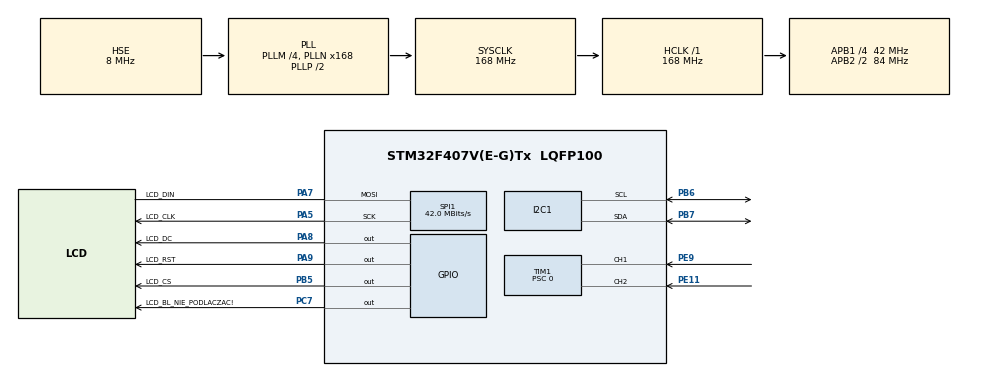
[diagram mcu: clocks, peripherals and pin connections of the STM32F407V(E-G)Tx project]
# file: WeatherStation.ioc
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Mcu.Family=STM32F4
Mcu.Name=STM32F407V(E-G)Tx
Mcu.Package=LQFP100
NVIC.PriorityGroup=NVIC_PRIORITYGROUP_4
NVIC.TIM4_IRQn=true\:0\:0\:false\:false\:true\:true
PA5.GPIO_Label=LCD_CLK
PA5.Mode=Simplex_Bidirectional_Master
PA5.Signal=SPI1_SCK
PA7.GPIO_Label=LCD_DIN
PA7.Mode=Simplex_Bidirectional_Master
PA7.Signal=SPI1_MOSI
PA8.GPIO_Label=LCD_DC
PA8.Signal=GPIO_Output
PA9.GPIO_Label=LCD_RST
PA9.Signal=GPIO_Output
PB5.GPIO_Label=LCD_CS
PB5.Signal=GPIO_Output
PB6.Mode=I2C
PB6.Signal=I2C1_SCL
PB7.Mode=I2C
PB7.Signal=I2C1_SDA
PC7.GPIO_Label=LCD_BL_NIE_PODLACZAC\!
PC7.Signal=GPIO_Output
PE11.Signal=S_TIM1_CH2
PE9.Signal=S_TIM1_CH1
PH0-OSC_IN.Mode=HSE-External-Oscillator
PH0-OSC_IN.Signal=RCC_OSC_IN
PH1-OSC_OUT.Mode=HSE-External-Oscillator
PH1-OSC_OUT.Signal=RCC_OSC_OUT
ProjectManager.HeapSize=0x200
ProjectManager.StackSize=0x400
ProjectManager.TargetToolchain=SW4STM32
RCC.48MHZClocksFreq_Value=84000000
RCC.AHBFreq_Value=168000000
RCC.APB1CLKDivider=RCC_HCLK_DIV4
RCC.APB1Freq_Value=42000000
RCC.APB1TimFreq_Value=84000000
RCC.APB2CLKDivider=RCC_HCLK_DIV2
RCC.APB2Freq_Value=84000000
RCC.APB2TimFreq_Value=168000000
RCC.CortexFreq_Value=168000000
RCC.HCLKFreq_Value=168000000
RCC.HSE_VALUE=8000000
RCC.HSI_VALUE=16000000
RCC.LSE_VALUE=32768
RCC.PLLM=4
RCC.PLLN=168
RCC.PLLSourceVirtual=RCC_PLLSOURCE_HSE
RCC.SYSCLKFreq_VALUE=168000000
RCC.SYSCLKSource=RCC_SYSCLKSOURCE_PLLCLK
RCC.VCOOutputFreq_Value=336000000
SH.S_TIM1_CH1.0=TIM1_CH1,Encoder_Interface
SH.S_TIM1_CH2.0=TIM1_CH2,Encoder_Interface
SPI1.CalculateBaudRate=42.0 MBits/s
SPI1.Direction=SPI_DIRECTION_1LINE
SPI1.Mode=SPI_MODE_MASTER
SPI1.VirtualType=VM_MASTER
TIM1.EncoderMode=TIM_ENCODERMODE_TI12
TIM1.IC1Filter=15
TIM1.IC2Filter=15
TIM1.Period=403
TIM1.Prescaler=0
TIM4.Period=8399
TIM4.Prescaler=9999
VP_TIM4_VS_ClockSourceINT.Mode=Internal
board=custom

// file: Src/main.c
/**
  ******************************************************************************
  * @file           : main.c
  * @brief          : Main program body
  ******************************************************************************
  ** This notice applies to any and all portions of this file
  * that are not between comment pairs USER CODE BEGIN and
  * USER CODE END. Other portions of this file, whether
  * inserted by the user or by software development tools
  * are owned by their respective copyright owners.
  *
  * COPYRIGHT(c) 2019 STMicroelectronics
  *
  * Redistribution and use in source and binary forms, with or without modification,
  * are permitted provided that the following conditions are met:
  *   1. Redistributions of source code must retain the above copyright notice,
  *      this list of conditions and the following disclaimer.
  *   2. Redistributions in binary form must reproduce the above copyright notice,
  *      this list of conditions and the following disclaimer in the documentation
  *      and/or other materials provided with the distribution.
  *   3. Neither the name of STMicroelectronics nor the names of its contributors
  *      may be used to endorse or promote products derived from this software
  *      without specific prior written permission.
  *
  * THIS SOFTWARE IS PROVIDED BY THE COPYRIGHT HOLDERS AND CONTRIBUTORS "AS IS"
  * AND ANY EXPRESS OR IMPLIED WARRANTIES, INCLUDING, BUT NOT LIMITED TO, THE
  * IMPLIED WARRANTIES OF MERCHANTABILITY AND FITNESS FOR A PARTICULAR PURPOSE ARE
  * DISCLAIMED. IN NO EVENT SHALL THE COPYRIGHT HOLDER OR CONTRIBUTORS BE LIABLE
  * FOR ANY DIRECT, INDIRECT, INCIDENTAL, SPECIAL, EXEMPLARY, OR CONSEQUENTIAL
  * DAMAGES (INCLUDING, BUT NOT LIMITED TO, PROCUREMENT OF SUBSTITUTE GOODS OR
  * SERVICES; LOSS OF USE, DATA, OR PROFITS; OR BUSINESS INTERRUPTION) HOWEVER
  * CAUSED AND ON ANY THEORY OF LIABILITY, WHETHER IN CONTRACT, STRICT LIABILITY,
  * OR TORT (INCLUDING NEGLIGENCE OR OTHERWISE) ARISING IN ANY WAY OUT OF THE USE
  * OF THIS SOFTWARE, EVEN IF ADVISED OF THE POSSIBILITY OF SUCH DAMAGE.
  *
  ******************************************************************************
  */
#include "main.h"
#include "stm32f4xx_hal.h"

/* USER CODE BEGIN Includes */
#include <string.h>
#include <stdlib.h>
#include <math.h>
#include "bmp280.h"
#include "st7735.h"
#include "fonts.h"
#include "images/widgets.h"

#define RADIUS 0.04
#define KM_H 3.6
#define T_TIM 0.5
#define ANGLE 15
/* USER CODE END Includes */

I2C_HandleTypeDef hi2c1;

SPI_HandleTypeDef hspi1;

TIM_HandleTypeDef htim1;
TIM_HandleTypeDef htim4;

/* USER CODE BEGIN PV */
/* Private variables ---------------------------------------------------------*/
BMP280_HandleTypedef bmp280;

float pressure, temperature, humidity;
float pressure_hPa;

volatile uint16_t pulse_count;
volatile uint16_t position1 = 0;
volatile uint16_t position2 = 0;
volatile uint16_t angle_remainder;
volatile float angular_velocity;
volatile float velocity;
/* USER CODE END PV */

void SystemClock_Config(void);
static void MX_GPIO_Init(void);
static void MX_I2C1_Init(void);
static void MX_TIM1_Init(void);
static void MX_SPI1_Init(void);
static void MX_TIM4_Init(void);

/* USER CODE BEGIN PFP */
/* Private function prototypes -----------------------------------------------*/
void HAL_TIM_PeriodElapsedCallback(TIM_HandleTypeDef *htim) {
    if (htim->Instance == TIM4) {
        pulse_count = TIM1->CNT;
        position2 = position1;
        position1 = pulse_count / 2;
        angle_remainder = abs(position2 - position1);
        if (angle_remainder > 300)
            angle_remainder = 400 - angle_remainder;
        angular_velocity = (angle_remainder * ANGLE / T_TIM) * M_PI / 180;
        velocity = angular_velocity * RADIUS * KM_H;
    }

}
/* USER CODE END PFP */

/* USER CODE BEGIN 0 */

/**
 * Initialize BME280 temperature, pressure and humidity sensor
 */
void sensor_init() {
	bmp280_init_default_params(&bmp280.params);
	bmp280.addr = BMP280_I2C_ADDRESS_1;
	bmp280.i2c = &hi2c1;
	bmp280_init(&bmp280, &bmp280.params);
}

/**
 * Initialize ST7735S LCD display
 */
void LCD_init() {
    ST7735_Init();
    ST7735_DrawImage(0, 0, 160, 128, (uint16_t *) widget);
    HAL_Delay(3000);

    ST7735_FillScreen(ST7735_BGCOLOR);
    ST7735_DrawImage(10, 7, 24, 24, (uint16_t *) termometer);
    ST7735_DrawImage(10, 37, 24, 24, (uint16_t *) barometer);
    ST7735_DrawImage(10, 67, 24, 24, (uint16_t *) humidity_img);
    ST7735_DrawImage(10, 97, 24, 24, (uint16_t *) wind);

    ST7735_DrawCircle(104, 15, 3, 0, 2, ST7735_BLACK);
    ST7735_WriteString(111, 11, "C", Font_11x18, ST7735_BLACK, ST7735_BGCOLOR);
    ST7735_WriteString(120, 41, "hPa", Font_11x18, ST7735_BLACK, ST7735_BGCOLOR);
    ST7735_WriteString(100, 71, "%", Font_11x18, ST7735_BLACK, ST7735_BGCOLOR);
    ST7735_WriteString(100, 101, "km/h", Font_11x18, ST7735_BLACK, ST7735_BGCOLOR);
}

void LCD_loop() {
    ST7735_WriteNumber(40, 11, temperature, Font_11x18, ST7735_BLACK, ST7735_BGCOLOR);
    ST7735_WriteNumber(40, 41, pressure_hPa, Font_11x18, ST7735_BLACK, ST7735_BGCOLOR);
    ST7735_WriteNumber(40, 71, humidity, Font_11x18, ST7735_BLACK, ST7735_BGCOLOR);
    if (velocity < 10) {
        ST7735_FillRectangle(84, 101, 11, 18, ST7735_BGCOLOR);
        ST7735_WriteNumber(40, 101, velocity, Font_11x18, ST7735_BLACK, ST7735_BGCOLOR);
    } else {
        ST7735_WriteNumber(40, 101, velocity, Font_11x18, ST7735_BLACK, ST7735_BGCOLOR);
    }
    HAL_Delay(500);
}

/* USER CODE END 0 */

int main(void)
{

  /* MCU Configuration----------------------------------------------------------*/

  /* Reset of all peripherals, Initializes the Flash interface and the Systick. */
  HAL_Init();

  /* Configure the system clock */
  SystemClock_Config();

  /* Initialize all configured peripherals */
  MX_GPIO_Init();
  MX_I2C1_Init();
  MX_TIM1_Init();
  MX_SPI1_Init();
  MX_TIM4_Init();
  /* USER CODE BEGIN 2 */
  	sensor_init();
    HAL_TIM_Encoder_Start(&htim1, TIM_CHANNEL_ALL);
    LCD_init();

    HAL_TIM_Base_Start_IT(&htim4);
  /* USER CODE END 2 */

  /* Infinite loop */
    while (1)
    {

  /* USER CODE BEGIN 3 */
        HAL_Delay(100);
        bmp280_read_float(&bmp280, &temperature, &pressure, &humidity);
        pressure_hPa = pressure / 100;

        LCD_loop();
    }
  /* USER CODE END 3 */

}

void SystemClock_Config(void)
{

  RCC_OscInitTypeDef RCC_OscInitStruct;
  RCC_ClkInitTypeDef RCC_ClkInitStruct;

    /**Configure the main internal regulator output voltage
    */
  __HAL_RCC_PWR_CLK_ENABLE();

  __HAL_PWR_VOLTAGESCALING_CONFIG(PWR_REGULATOR_VOLTAGE_SCALE1);

    /**Initializes the CPU, AHB and APB busses clocks
    */
  RCC_OscInitStruct.OscillatorType = RCC_OSCILLATORTYPE_HSE;
  RCC_OscInitStruct.HSEState = RCC_HSE_ON;
  RCC_OscInitStruct.PLL.PLLState = RCC_PLL_ON;
  RCC_OscInitStruct.PLL.PLLSource = RCC_PLLSOURCE_HSE;
  RCC_OscInitStruct.PLL.PLLM = 4;
  RCC_OscInitStruct.PLL.PLLN = 168;
  RCC_OscInitStruct.PLL.PLLP = RCC_PLLP_DIV2;
  RCC_OscInitStruct.PLL.PLLQ = 4;
  if (HAL_RCC_OscConfig(&RCC_OscInitStruct) != HAL_OK)
  {
    _Error_Handler(__FILE__, __LINE__);
  }

    /**Initializes the CPU, AHB and APB busses clocks
    */
  RCC_ClkInitStruct.ClockType = RCC_CLOCKTYPE_HCLK|RCC_CLOCKTYPE_SYSCLK
                              |RCC_CLOCKTYPE_PCLK1|RCC_CLOCKTYPE_PCLK2;
  RCC_ClkInitStruct.SYSCLKSource = RCC_SYSCLKSOURCE_PLLCLK;
  RCC_ClkInitStruct.AHBCLKDivider = RCC_SYSCLK_DIV1;
  RCC_ClkInitStruct.APB1CLKDivider = RCC_HCLK_DIV4;
  RCC_ClkInitStruct.APB2CLKDivider = RCC_HCLK_DIV2;

  if (HAL_RCC_ClockConfig(&RCC_ClkInitStruct, FLASH_LATENCY_5) != HAL_OK)
  {
    _Error_Handler(__FILE__, __LINE__);
  }

    /**Configure the Systick interrupt time
    */
  HAL_SYSTICK_Config(HAL_RCC_GetHCLKFreq()/1000);

    /**Configure the Systick
    */
  HAL_SYSTICK_CLKSourceConfig(SYSTICK_CLKSOURCE_HCLK);

  /* SysTick_IRQn interrupt configuration */
  HAL_NVIC_SetPriority(SysTick_IRQn, 0, 0);
}

/* I2C1 init function */
static void MX_I2C1_Init(void)
{

  hi2c1.Instance = I2C1;
  hi2c1.Init.ClockSpeed = 100000;
  hi2c1.Init.DutyCycle = I2C_DUTYCYCLE_2;
  hi2c1.Init.OwnAddress1 = 0;
  hi2c1.Init.AddressingMode = I2C_ADDRESSINGMODE_7BIT;
  hi2c1.Init.DualAddressMode = I2C_DUALADDRESS_DISABLE;
  hi2c1.Init.OwnAddress2 = 0;
  hi2c1.Init.GeneralCallMode = I2C_GENERALCALL_DISABLE;
  hi2c1.Init.NoStretchMode = I2C_NOSTRETCH_DISABLE;
  if (HAL_I2C_Init(&hi2c1) != HAL_OK)
  {
    _Error_Handler(__FILE__, __LINE__);
  }

}

/* SPI1 init function */
static void MX_SPI1_Init(void)
{

  /* SPI1 parameter configuration*/
  hspi1.Instance = SPI1;
  hspi1.Init.Mode = SPI_MODE_MASTER;
  hspi1.Init.Direction = SPI_DIRECTION_1LINE;
  hspi1.Init.DataSize = SPI_DATASIZE_8BIT;
  hspi1.Init.CLKPolarity = SPI_POLARITY_LOW;
  hspi1.Init.CLKPhase = SPI_PHASE_1EDGE;
  hspi1.Init.NSS = SPI_NSS_SOFT;
  hspi1.Init.BaudRatePrescaler = SPI_BAUDRATEPRESCALER_2;
  hspi1.Init.FirstBit = SPI_FIRSTBIT_MSB;
  hspi1.Init.TIMode = SPI_TIMODE_DISABLE;
  hspi1.Init.CRCCalculation = SPI_CRCCALCULATION_DISABLE;
  hspi1.Init.CRCPolynomial = 10;
  if (HAL_SPI_Init(&hspi1) != HAL_OK)
  {
    _Error_Handler(__FILE__, __LINE__);
  }

}

/* TIM1 init function */
static void MX_TIM1_Init(void)
{

  TIM_Encoder_InitTypeDef sConfig;
  TIM_MasterConfigTypeDef sMasterConfig;

  htim1.Instance = TIM1;
  htim1.Init.Prescaler = 0;
  htim1.Init.CounterMode = TIM_COUNTERMODE_UP;
  htim1.Init.Period = 800;
  htim1.Init.ClockDivision = TIM_CLOCKDIVISION_DIV1;
  htim1.Init.RepetitionCounter = 0;
  sConfig.EncoderMode = TIM_ENCODERMODE_TI12;
  sConfig.IC1Polarity = TIM_ICPOLARITY_RISING;
  sConfig.IC1Selection = TIM_ICSELECTION_DIRECTTI;
  sConfig.IC1Prescaler = TIM_ICPSC_DIV1;
  sConfig.IC1Filter = 15;
  sConfig.IC2Polarity = TIM_ICPOLARITY_RISING;
  sConfig.IC2Selection = TIM_ICSELECTION_DIRECTTI;
  sConfig.IC2Prescaler = TIM_ICPSC_DIV1;
  sConfig.IC2Filter = 15;
  if (HAL_TIM_Encoder_Init(&htim1, &sConfig) != HAL_OK)
  {
    _Error_Handler(__FILE__, __LINE__);
  }

  sMasterConfig.MasterOutputTrigger = TIM_TRGO_RESET;
  sMasterConfig.MasterSlaveMode = TIM_MASTERSLAVEMODE_DISABLE;
  if (HAL_TIMEx_MasterConfigSynchronization(&htim1, &sMasterConfig) != HAL_OK)
  {
    _Error_Handler(__FILE__, __LINE__);
  }

}

/* TIM4 init function */
static void MX_TIM4_Init(void)
{

  TIM_ClockConfigTypeDef sClockSourceConfig;
  TIM_MasterConfigTypeDef sMasterConfig;

  htim4.Instance = TIM4;
  htim4.Init.Prescaler = 9999;
  htim4.Init.CounterMode = TIM_COUNTERMODE_UP;
  htim4.Init.Period = 8399;
  htim4.Init.ClockDivision = TIM_CLOCKDIVISION_DIV1;
  if (HAL_TIM_Base_Init(&htim4) != HAL_OK)
  {
    _Error_Handler(__FILE__, __LINE__);
  }

  sClockSourceConfig.ClockSource = TIM_CLOCKSOURCE_INTERNAL;
  if (HAL_TIM_ConfigClockSource(&htim4, &sClockSourceConfig) != HAL_OK)
  {
    _Error_Handler(__FILE__, __LINE__);
  }

  sMasterConfig.MasterOutputTrigger = TIM_TRGO_RESET;
  sMasterConfig.MasterSlaveMode = TIM_MASTERSLAVEMODE_DISABLE;
  if (HAL_TIMEx_MasterConfigSynchronization(&htim4, &sMasterConfig) != HAL_OK)
  {
    _Error_Handler(__FILE__, __LINE__);
  }

}

/** Configure pins as
        * Analog
        * Input
        * Output
        * EVENT_OUT
        * EXTI
*/
static void MX_GPIO_Init(void)
{

  GPIO_InitTypeDef GPIO_InitStruct;

  /* GPIO Ports Clock Enable */
  __HAL_RCC_GPIOH_CLK_ENABLE();
  __HAL_RCC_GPIOA_CLK_ENABLE();
  __HAL_RCC_GPIOE_CLK_ENABLE();
  __HAL_RCC_GPIOC_CLK_ENABLE();
  __HAL_RCC_GPIOB_CLK_ENABLE();

  /*Configure GPIO pin Output Level */
  HAL_GPIO_WritePin(LCD_BL_GPIO_Port, LCD_BL_Pin, GPIO_PIN_RESET);

  /*Configure GPIO pin Output Level */
  HAL_GPIO_WritePin(GPIOA, LCD_DC_Pin|LCD_RST_Pin, GPIO_PIN_RESET);

  /*Configure GPIO pin Output Level */
  HAL_GPIO_WritePin(LCD_CS_GPIO_Port, LCD_CS_Pin, GPIO_PIN_RESET);

  /*Configure GPIO pin : LCD_BL_Pin */
  GPIO_InitStruct.Pin = LCD_BL_Pin;
  GPIO_InitStruct.Mode = GPIO_MODE_OUTPUT_PP;
  GPIO_InitStruct.Pull = GPIO_NOPULL;
  GPIO_InitStruct.Speed = GPIO_SPEED_FREQ_LOW;
  HAL_GPIO_Init(LCD_BL_GPIO_Port, &GPIO_InitStruct);

  /*Configure GPIO pins : LCD_DC_Pin LCD_RST_Pin */
  GPIO_InitStruct.Pin = LCD_DC_Pin|LCD_RST_Pin;
  GPIO_InitStruct.Mode = GPIO_MODE_OUTPUT_PP;
  GPIO_InitStruct.Pull = GPIO_NOPULL;
  GPIO_InitStruct.Speed = GPIO_SPEED_FREQ_LOW;
  HAL_GPIO_Init(GPIOA, &GPIO_InitStruct);

  /*Configure GPIO pin : LCD_CS_Pin */
  GPIO_InitStruct.Pin = LCD_CS_Pin;
  GPIO_InitStruct.Mode = GPIO_MODE_OUTPUT_PP;
  GPIO_InitStruct.Pull = GPIO_NOPULL;
  GPIO_InitStruct.Speed = GPIO_SPEED_FREQ_LOW;
  HAL_GPIO_Init(LCD_CS_GPIO_Port, &GPIO_InitStruct);

}

void _Error_Handler(char *file, int line)
{
    while(1)
    {
    }
}

/************************ (C) COPYRIGHT STMicroelectronics *****END OF FILE****/
